# PRU_ICSS_0_IEP_local register map
Vendor: Texas Instruments
Peripheral module from a debugger description file (folder 66AK2G0x_66AK2G1x).
Registers are 32-bit, read-write, reset 0x0 unless marked. A register's access mark holds for its fields unless they carry their own. Offsets are as the file gives them; lines under a group give offsets from that group; [hi:lo] are bit positions; {n}, {i} and the like mark numbered series; 'fields as' and 'values as' point back to an identical list; <NAME> marks a mode.

## PRU_ICSS_0_IEP
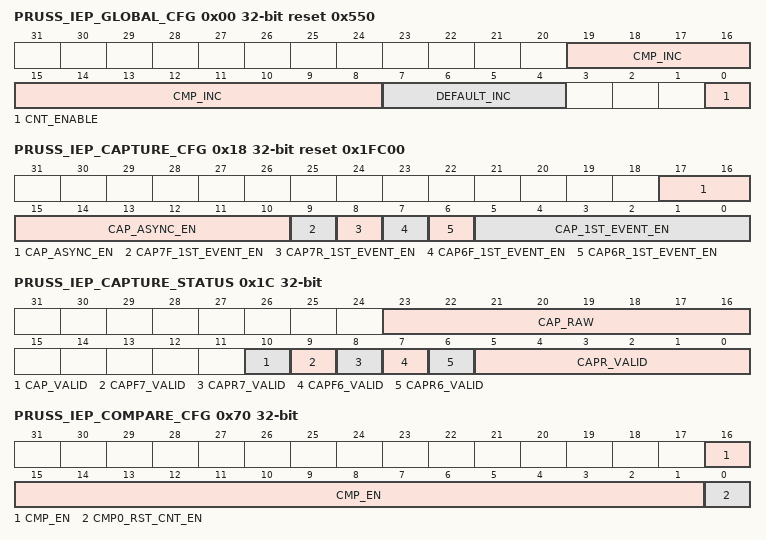
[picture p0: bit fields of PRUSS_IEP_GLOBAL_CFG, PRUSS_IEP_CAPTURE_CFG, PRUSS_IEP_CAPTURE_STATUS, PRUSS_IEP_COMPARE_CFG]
0x00 PRUSS_IEP_GLOBAL_CFG access per field reset 0x550
  [19:8] CMP_INC rw — Defines the increment value when compensation is active
  [7:4] DEFAULT_INC rw — Defines the default increment value
  [0] CNT_ENABLE rw — Counter enable. 0h: Disables the counter. The counter maintains the current count. 1h: Enables the counter.
0x04 PRUSS_IEP_STATUS access not given
  [0] CNT_OVF — Counter overflow status. 0h: No overflow (access RWr1Clr)
0x08 PRUSS_IEP_COMPENSATION access per field
  [23:0] COMPEN_CNT rw — Compensation counter. Read returns the current COMPEN_CNT value. 0h: Compensation is disabled and counter will increment by DEFAULT_INC. Nh: Compensation is enabled until COMPEN_CNT decrements to 0. The COMPEN_CNT value decrements on every IEP_CLK cycle. When COMPEN_CNT is greater than 0, then count value increments by CMP_INC. NOTE: SLOW_COMPEN_CNT MUST be set to zero IF COMPEN_CNT is not zero.
0x0C PRUSS_IEP_SLOW_COMPENSATION
  [31:0] SLOW_COMPEN_CNT — Slow compensation counter. Write 0h: Slow compensation is disabled and counter will increment by DEFAULT_INC. Write Nh: Compensation is enabled for 1 count for every SLOW_COMPEN_CNT cycle, this is free running and continuous until software clears the MMR. For example, SLOW_COMPEN_CNT = 16, every 16 clock cycles the compensation value is used for 1 count. Note: COMPEN_CNT MUST be set to zero IF SLOW_COMPEN_CNT is not zero. Software can read the number of cycles left until the compensation event. For example, software writes SLOW_COMPEN_CNT = 100h and reads SLOW_COMPEN_CNT = 7h. This means in 6 more IEP_CLK cycles before the counter reaches 1h for the compensation event. If software writes SLOW_COMPEN_CNT = 8000h before compensation event, then the counter will reset to 8000h.
0x10 PRUSS_IEP_LOW_COUNTER
  [31:0] COUNT — 64 bit count value (lower 32-bits). Increments by (DEFAULT_INC or CMP_INC) on every positive edge of ICSS_IEP_CLK (200MHz) or ICSS_VCLK_CLK.
0x14 PRUSS_IEP_HIGH_COUNTER
  [31:0] COUNT — 64 bit count value (upper 32-bits). Increments by (DEFAULT_INC or CMP_INC) on every positive edge of ICSS_IEP_CLK (200MHz) or ICSS_VCLK_CLK.
0x18 PRUSS_IEP_CAPTURE_CFG access per field reset 0x1FC00
  [17:10] CAP_ASYNC_EN rw — Synchronization of the capture inputs to the ICSS_IEP_CLK/ ICSS_VCLK_CLK enable. Note if input capture signal is asynchronous to ICSS_IEP_CLK, enabling synchronization will cause the capture contents to be invalid. CAP_ASYNC_EN[n] maps to CAPR[n]. 0h: Disable synchronization 1h: Enable synchronization
  [9] CAP7F_1ST_EVENT_EN rw — Capture 1st Event Enable for CAP7F. 0h: Continues mode. The capture status is not set when events occur. 1h: First Event mode. The capture status is set when the first event occurs and must be cleared before new data will fill buffer. Time value is captured when first event occurs and held until time is read.
  [8] CAP7R_1ST_EVENT_EN rw — Capture 1st Event Enable for CAP7R. 0h: Continues mode. The capture status is not set when events occur. 1h: First Event mode. The capture status is set when the first event occurs and must be cleared before new data will fill buffer. Time value is captured when first event occurs and held until time is read.
  [7] CAP6F_1ST_EVENT_EN rw — Capture 1st Event Enable for CAP6F. 0h: Continues mode. The capture status is not set when events occur. 1h: First Event mode. The capture status is set when the first event occurs and must be cleared before new data will fill buffer. Time value is captured when first event occurs and held until time is read.
  [6] CAP6R_1ST_EVENT_EN rw — Capture 1st Event Enable for CAP6R. 0h: Continues mode. The capture status is not set when events occur. 1h: First Event mode. The capture status is set when the first event occurs and must be cleared before new data will fill buffer. Time value is captured when first event occurs and held until time is read.
  [5:0] CAP_1ST_EVENT_EN rw — Capture 1st Event Enable for registers. CAP_1ST_EVENT_EN[n] maps to CAPR[n]. 0h: Continues mode. The capture status is not set when events occur. 1h: First Event mode. The capture status is set when the first event occurs and must be cleared before new data will fill buffer. Time value is captured when first event occurs and held until time is read.
0x1C PRUSS_IEP_CAPTURE_STATUS ro
  [23:16] CAP_RAW — Raw/Current status bit for each of the capture registers, where CAP_RAW[n] maps to CAPR[n]. 0h: Current state is low. 1h: Current state is high.
  [10] CAP_VALID — Valid status for capture function. Reflects the ORed result from CAP_STATUS[9:0]. 0h: No Hit for any capture event, i.e., there are all 0 in CAP_STATUS[9:0]. 1h: Hit for 1 or more captures events is pending, i.e., there has at least one value equal to 1 in CAP_STATUS[9:0].
  [9] CAPF7_VALID — Valid status for CAPF7 (fall). 0h: No Hit, no capture event occurred 1h: Hit, capture event occurred
  [8] CAPR7_VALID — Valid status for CAPR7 (rise). 0h: No Hit, no capture event occurred 1h: Hit, capture event occurred
  [7] CAPF6_VALID — Valid status for CAPF6 (fall). 0h: No Hit, no capture event occurred 1h: Hit, capture event occurred
  [6] CAPR6_VALID — Valid status for CAPR6 (rise). 0h: No Hit, no capture event occurred 1h: Hit, capture event occurred
  [5:0] CAPR_VALID — Valid status bit for each compare register, where CAPR_VALID[n] maps to CAPR[n] (rise). 0h: No Hit, no capture event occurred 1h: Hit, capture event occurred
{0x20+8i} PRUSS_IEP_CAPTURE_RISE{i:02} ro (i=0..5)
  [31:0] CAPR — Value captured for CAPR&lt;i&gt; (fall) event, where i = 0 to 5. Lower 32-bits.
0x24 PRUSS_IEP_CAPTURE_RISE10 ro
  [31:0] CAPR — Value captured for CAPR&lt;i&gt; (rise) event, where i = 0 to 5. Upper 32-bits.
0x2C PRUSS_IEP_CAPTURE_RISE11 ro
  fields as PRUSS_IEP_CAPTURE_RISE10
0x34 PRUSS_IEP_CAPTURE_RISE12 ro
  fields as PRUSS_IEP_CAPTURE_RISE10
0x3C PRUSS_IEP_CAPTURE_RISE13 ro
  fields as PRUSS_IEP_CAPTURE_RISE10
0x44 PRUSS_IEP_CAPTURE_RISE14 ro
  fields as PRUSS_IEP_CAPTURE_RISE10
0x4C PRUSS_IEP_CAPTURE_RISE15 ro
  fields as PRUSS_IEP_CAPTURE_RISE10
0x50 PRUSS_IEP_CAPTURE_RISE06 ro
  [31:0] CAPR — Value captured for CAPR6 event. Lower 32-bits.
0x54 PRUSS_IEP_CAPTURE_RISE16 ro
  [31:0] CAPR — Value captured for CAPR6 event. Upper 32-bits.
0x58 PRUSS_IEP_CAPTURE_FALL06 ro
  [31:0] CAPF — Value captured for CAPF6 (fall) event. Lower 32-bits.
0x5C PRUSS_IEP_CAPTURE_FALL16 ro
  [31:0] CAPF — Value captured for CAPF6 (fall) event. Lower 32-bits.
0x60 PRUSS_IEP_CAPTURE_RISE07 ro
  [31:0] CAPR — Value captured for CAPR7 (rise) event. Lower 32-bits.
0x64 PRUSS_IEP_CAPTURE_RISE17 ro
  [31:0] CAPR — Value captured for CAPR7 (rise) event. Upper 32-bits.
0x68 PRUSS_IEP_CAPTURE_FALL07 ro
  [31:0] CAPF — Value captured for CAPF7 (fall) event. Lower 32-bits.
0x6C PRUSS_IEP_CAPTURE_FALL17 ro
  [31:0] CAPF — Value captured for CAPF7 (fall) event. Upper 32-bits.
0x70 PRUSS_IEP_COMPARE_CFG access per field
  [16:1] CMP_EN rw — Enable bits for each of the compare registers
  [0] CMP0_RST_CNT_EN rw — Enable the reset of the counter
0x74 PRUSS_IEP_COMPARE_STATUS access not given
  [15:0] CMP_HIT — Status bit for each of the compare registers. 'Match' indicates the current counter is greater than or equal to the compare value. Note it is the firmware's responsibility to handle the IEP overflow. (access RWr1Clr)
{0x78+8i} PRUSS_IEP_COMPARE{i:02} (i=0..7)
  [31:0] CMP — Compare {i} low value
{0x2C+8i} PRUSS_IEP_COMPARE{i} (i=10..17)
  [31:0] CMP — Compare {i-10} high value
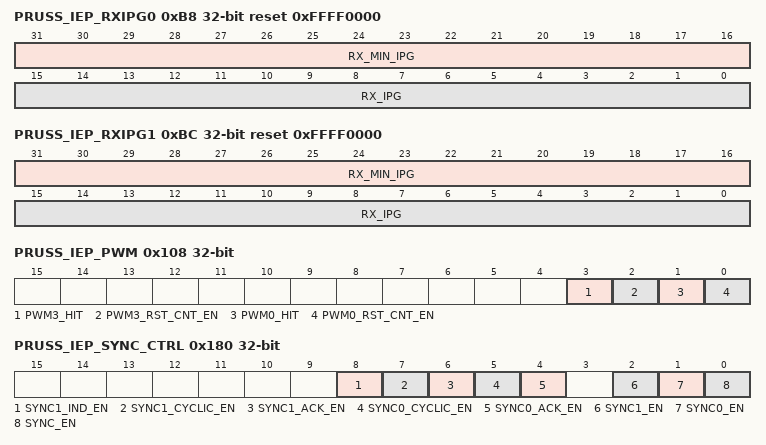
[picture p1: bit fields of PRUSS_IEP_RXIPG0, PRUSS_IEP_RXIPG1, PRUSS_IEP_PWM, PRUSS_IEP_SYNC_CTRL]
0xB8 PRUSS_IEP_RXIPG0 access per field reset 0xFFFF0000
  [31:16] RX_MIN_IPG rw — Defines the minimum number of ICSS_IEP_CLK/ICCS_VCLK_CLK cycles that is RX_DV is sampled low. It stores the smallest RX_IPG duration. It can be read at any time and gets updated after RX_IPG is updated, if RX_MIN_IPG is greater than RX_IPG.
  [15:0] RX_IPG ro — Records the current number of ICSS_IEP_CLK/ICSS_VCLK_CLK cycles RX_DV is sampled low. Value is updated after RX_DV transitions from low to high. It will saturate at FFFFh.
0xBC PRUSS_IEP_RXIPG1 access per field reset 0xFFFF0000
  [31:16] RX_MIN_IPG rw — Defines the minimum number of ICSS_IEP_CLK/ICSS_VCLK_CLK cycles that is RX_DV is sampled low. It stores the smallest RX_IPG duration. It can be read at any time and gets updated after RX_IPG is updated, if RX_MIN_IPG is greater than RX_IPG.
  [15:0] RX_IPG ro — Records the current number of ICSS_IEP_CLK/ICSS_VCLK_CLK cycles RX_DV is sampled low. Value is updated after RX_DV transitions from low to high. It will saturate at FFFFh.
0xC0 PRUSS_IEP_COMPARE08
  [31:0] CMP — Compare 8 low value
0xC4 PRUSS_IEP_COMPARE18
  [31:0] CMP — Reset value (upper 32-bits). This register enables SW to define the reset state of the Master Counter, which can be reset by the following events (if enabled): CMP0 event; eHRPWM0_SYNCO event; eHRPWM3_SYNCO event. The RESET_VAL should be in increments of the DEFAULT_INC (default state is 5). For example, 0000_000Ah.
0xC8 PRUSS_IEP_COMPARE09
  [31:0] CMP — Compare 9 low value
0xCC PRUSS_IEP_COMPARE19
  [31:0] CMP — Compare 9 high value
{0x80+8i} PRUSS_IEP_COMPARE{i:03} (i=10..15)
  [31:0] CMP — Compare {i} low value
0xD4 PRUSS_IEP_COMPARE110
  [31:0] CMP — Compare 10 high value
0xDC PRUSS_IEP_COMPARE111
  [31:0] CMP — Compare 11 high value
0xE4 PRUSS_IEP_COMPARE112
  [31:0] CMP — Compare 12 high value
0xEC PRUSS_IEP_COMPARE113
  [31:0] CMP — Compare 13 high value
0xF4 PRUSS_IEP_COMPARE114
  [31:0] CMP — Compare 14 high value
0xFC PRUSS_IEP_COMPARE115
  [31:0] CMP — Compare 15 high value
0x100 PRUSS_IEP_LOW_COUNTER_RESET_VALUE
  [31:0] RESET_VAL — Reset value (lower 32-bits). This register enables SW to define the reset state of the Master Counter, which can be reset by the following events (if enabled): CMP0 event; eHRPWM0_SYNCO event; eHRPWM3_SYNCO event. The RESET_VAL should be in increments of the DEFAULT_INC (default state is 5). For example, 0000_000Ah.
0x104 PRUSS_IEP_HIGH_COUNTER_RESET_VALUE
  [31:0] RESET_VAL — This enables SW to define the reset state of the Master counter when it gets reset do to the following 3 possible events if enabled: CMP0 event; eHRPWM0_SYNCO event; eHRPWM3_SYNCO event. It should be in increments of the DEFAULT_INC, default state is 5 For example, 0000_000Ah
0x108 PRUSS_IEP_PWM access not given
  [3] PWM3_HIT — The raw status bit of eHRPWM3_SYNCO event. 0h: No eHRPWM3_SYNCO event 1h: eHRPWM3_SYNCO event occurred Write 1h to Clear. (access RW1Clr)
  [2] PWM3_RST_CNT_EN rw — Enable the reset of the counter by a eHRPWM3_SYNCO event. 0h: Disable 1h: Enable the reset of the counter if a eHRPWM3_SYNCO event occurs
  [1] PWM0_HIT — The raw status bit of eHRPWM0_SYNCO event. 0h: No eHRPWM0_SYNCO event 1h: eHRPWM0_SYNCO event occurred Write 1 to Clear. (access RW1Clr)
  [0] PWM0_RST_CNT_EN rw — Enable the reset of the counter by a eHRPWM0_SYNCO event. 0h: Disable 1h: Enable the reset of the counter if a eHRPWM0_SYNCO event occurs
0x180 PRUSS_IEP_SYNC_CTRL access per field
  [8] SYNC1_IND_EN rw — SYNC1 independent mode enable. Independent mode means the SYNC1 signal can be different from SYNC0. 0h: Dependent mode
  [7] SYNC1_CYCLIC_EN rw — SYNC1 single shot or cyclic/auto generation mode enable 0h: Disable, single shot mode
  [6] SYNC1_ACK_EN rw — SYNC1 acknowledgement mode enable 0h: Disable, SYNC1 will go low after pulse width is met.
  [5] SYNC0_CYCLIC_EN rw — SYNC0 single shot or cyclic/auto generation mode enable 0h: Disable, single shot mode
  [4] SYNC0_ACK_EN rw — SYNC0 acknowledgement mode enable 0h: Disable, SYNC0 will go low after pulse width is met.
  [2] SYNC1_EN rw — SYNC1 generation enable 0h: Disable SYNC1 generation. If SYNC1 is low, it will stop immediately. If SYNC1 is high, it will stop after SYNC1 goes low
  [1] SYNC0_EN rw — SYNC0 generation enable 0h: Disable SYNC0 generation. If SYNC0 is low, it will stop immediately If SYNC0 is high, it will stop after SYNC0 goes low
  [0] SYNC_EN rw — SYNC generation enable 0h: Disable the generation and clocking of SYNC0 and SYNC1 logic. If SYNC0 AND SYNC1 is low, it will stop immediately. If SYNC0 OR SYNC1 is high, it will stop after SYCN0 AND SYNC1 goes low. Note that you might get 1 extra high pulse if this is disabled during a high pulse of one and the 2nd pulse goes high before the last pulse low if you do not de-assert sync0_en and sync1_en at the same time. SW should always de-assert both sync1_en and sync0_en at the same time as sync_en is de-asserted
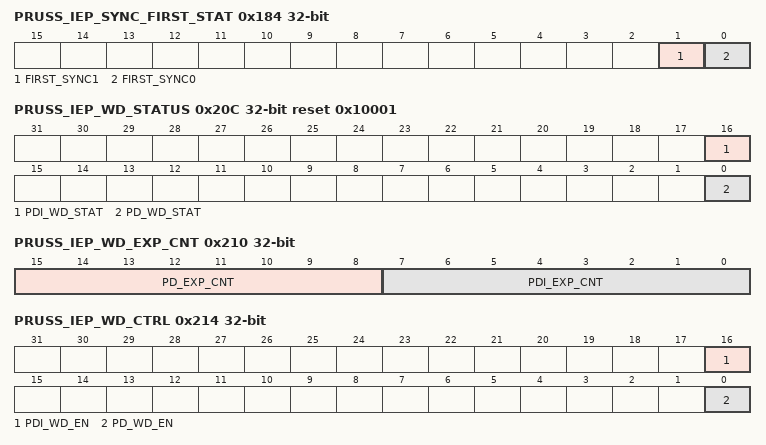
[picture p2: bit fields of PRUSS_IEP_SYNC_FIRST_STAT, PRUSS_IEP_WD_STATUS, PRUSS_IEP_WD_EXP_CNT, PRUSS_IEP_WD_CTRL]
0x184 PRUSS_IEP_SYNC_FIRST_STAT ro
  [1] FIRST_SYNC1 — SYNC1 First Event status
  [0] FIRST_SYNC0 — SYNC0 First Event status
0x188 PRUSS_IEP_SYNC0_STAT access not given
  [0] SYNC0_PEND — SYNC0 pending state (access RWr1Clr)
0x18C PRUSS_IEP_SYNC1_STAT access not given
  [0] SYNC1_PEND — SYNC1 pending state (access RWr1Clr)
0x190 PRUSS_IEP_SYNC_PWIDTH
  [31:0] SYNC_HPW — Defines the number of clock cycles SYNC0/1 will be high.
0x194 PRUSS_IEP_SYNC0_PERIOD reset 0x1
  [31:0] SYNC0_PERIOD — Defines the period between the rising edges of SYNC0.
0x198 PRUSS_IEP_SYNC1_DELAY
  [31:0] SYNC1_DELAY — When SYNC1_IND_EN = 0, defines number of clock cycles from the start of SYNC0 to the start of SYNC1.
0x19C PRUSS_IEP_SYNC_START
  [31:0] SYNC_START — Defines the start time after the activation event.
0x200 PRUSS_IEP_WD_PREDIV access per field reset 0x4E20
  [15:0] PRE_DIV rw — Defines the number of ICSS_IEP_CLK cycles per WD clock event. Note that the WD clock is a free-running clock. The value 0x4e20 (or 20000) generates a rate of 100 us if ICSS_IEP_CLK is 200 MHz.
0x204 PRUSS_IEP_PDI_WD_TIM access per field reset 0x3E8
  [15:0] PDI_WD_TIME rw — Defines the number of WD ticks (or increments) for PDI WD, that is, the number of WD increments. If
0x208 PRUSS_IEP_PD_WD_TIM access per field reset 0x3E8
  [15:0] PD_WD_TIME rw — Defines the number of WD ticks (or increments) for PD WD, that is, the number of WD increments.
0x20C PRUSS_IEP_WD_STATUS ro reset 0x10001
  [16] PDI_WD_STAT — WD PDI status.
  [0] PD_WD_STAT — WD PD status (triggered by Sync Mangers status).
0x210 PRUSS_IEP_WD_EXP_CNT access not given
  [15:8] PD_EXP_CNT — WD PD expiration counter. Counter increments on every PD time out and stops at FFh. (access RWrClr)
  [7:0] PDI_EXP_CNT — WD PDI expiration counter. Counter increments on every PDI time out and stops at FFh. (access RWrClr)
0x214 PRUSS_IEP_WD_CTRL access per field
  [16] PDI_WD_EN rw — Watchdog PDI
  [0] PD_WD_EN rw — Watchdog PD
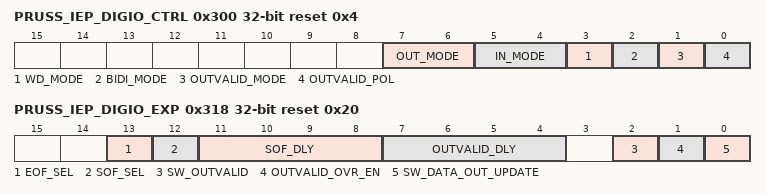
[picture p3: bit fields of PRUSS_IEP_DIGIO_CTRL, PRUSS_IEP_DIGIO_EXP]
0x300 PRUSS_IEP_DIGIO_CTRL access per field reset 0x4
  [7:6] OUT_MODE rw — Defines events that triggers data out to be updated. Note if OUTVALID_MODE is set, then data out is forced to zero if a WD PD expiration occurs (PD_WD_EXP) from the WD block and pr&lt;k&gt;_edio_oe_ext = 1.
  [5:4] IN_MODE rw — Defines event that triggers data in to be sampled
  [3] WD_MODE rw — Defines Watchdog behavior
  [2] BIDI_MODE ro — Defines the digital input/output direction. NOTE THAT DUE TO INTEGRATION, ACTUAL MODE IS UNIDIRECTIONAL IN THIS DEVICE.
  [1] OUTVALID_MODE rw — Defines the outvalid mode behavior.
  [0] OUTVALID_POL ro — Defines OUTVALID polarity
0x304 PRUSS_IEP_DIGIO_STATUS ro
  [31:0] DIGIO_STAT — Reserved
0x308 PRUSS_IEP_DIGIO_DATA_IN ro reset not defined
  [31:0] DATA_IN — Data input. Digital inputs can be configured to be sampled in four ways.
0x30C PRUSS_IEP_DIGIO_DATA_IN_RAW ro reset not defined
  [31:0] DATA_IN_RAW — Data input which direct sample of PR&lt;k&gt;_EDIO_DATA[0:31]. Only PR&lt;k&gt;_EDIO_DATA[0:3] are exported to device pins in this device.
0x310 PRUSS_IEP_DIGIO_DATA_OUT
  [31:0] DATA_OUT — Data output. Digital outputs can be configured to be updated in four ways. 1h: Digital outputs are updated at the end of each frame (EOF mode). 2h: Digital outputs are updated with SYNC0 events 3h: Digital outputs are updated SYNC1 events. 4h: Digital outputs are updated at the end of a frame which triggered the Process Data Watchdog. Digital Outputs are only updated if the frame was correct (WD_TRIG mode). These can be configured by [7-6] OUT_MODE bit field in the PRUSS_IEP_DIGIO_CTRL.
0x314 PRUSS_IEP_DIGIO_DATA_OUT_EN
  [31:0] DATA_OUT_EN — Data input which controls tri-state of PR&lt;k&gt;_EDIO_DATA[0:3]
0x318 PRUSS_IEP_DIGIO_EXP access per field reset 0x20
  [13] EOF_SEL rw — Defines which RX_EOF is used for PR&lt;k&gt;_EDIO_DATA_IN[0:3] capture
  [12] SOF_SEL rw — Defines which RX_SOF is used for PR&lt;k&gt;_EDIO_DATA_IN[0:3] capture
  [11:8] SOF_DLY rw — Define the number of iep_clk (ICSS_IEP_CLK) cycle delay of SOF PR&lt;k&gt;_EDIO_DATA_IN[0:3] capture
  [7:4] OUTVALID_DLY rw — Define the number of iep_clk (ICSS_IEP_CLK) cycle delay on assertion of PR&lt;k&gt;_EDIO_OUTVALID. Min is 2 clock cycles. Max is 16 clock cycles
  [2] SW_OUTVALID rw — PR&lt;k&gt;_EDIO_OUTVALID = SW_OUTVALID, only if OUTVALID_OVR_EN is set.
  [1] OUTVALID_OVR_EN rw — Software override enable
  [0] SW_DATA_OUT_UPDATE rw — Defines the value of pr&lt;k&gt;_edio_data_out when OUTVALID_OVR_EN = 1.
